# ipro6s register map
Vendor: intelpro; Series: IPRO6S
CPU: ipro6s, little endian
Registers are 32-bit, read-write, reset 0x0 unless marked. A register's access mark holds for its fields unless they carry their own. Offsets are from the block's base; [hi:lo] are bit positions; {n}, {i} and the like mark numbered series.

## MCU_MISC
Base 0x30009000
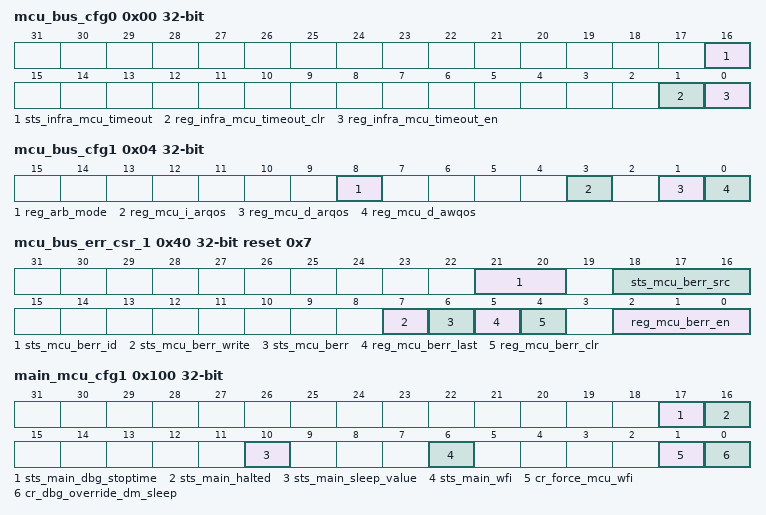
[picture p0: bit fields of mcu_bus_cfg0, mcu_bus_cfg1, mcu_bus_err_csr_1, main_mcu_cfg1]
0x00 mcu_bus_cfg0 (reset mask 0x3)
  [16] sts_infra_mcu_timeout ro — AHB Bus timeout status
  [1] reg_infra_mcu_timeout_clr — Bus timeout clear
  [0] reg_infra_mcu_timeout_en — Bus timeout enable: detect slave no reaponse in 1024 cycles
0x04 mcu_bus_cfg1
  [8] reg_arb_mode — Arbitration mode
  [3] reg_mcu_i_arqos — Main MCU AXI read QoS
  [1] reg_mcu_d_arqos — Main MCU AXI read QoS
  [0] reg_mcu_d_awqos — Main MCU AXI write QoS
0x40 mcu_bus_err_csr_1 reset 0x7 (reset mask 0x37)
  [21:20] sts_mcu_berr_id ro — Error id status
  [18:16] sts_mcu_berr_src ro — bus decode error source index(One hot) [ 0] - rom_tzsrg [ 1] - infra_mmcu_iport [ 2] - infra_mmcu_dport
  [7] sts_mcu_berr_write ro — Bus addr decode error write index
  [6] sts_mcu_berr ro — Bus addr decode error
  [5] reg_mcu_berr_last — Bus addr error monitor latch mode 1'b0 - Latch first error 1'b1 - Latch last error
  [4] reg_mcu_berr_clr — Bus addr decode error clear
  [2:0] reg_mcu_berr_en — bus decode error source index(One hot) [ 0] - rom_tzsrg [ 1] - infra_mmcu_iport [ 2] - infra_mmcu_dport
0x100 main_mcu_cfg1 (reset mask 0x3)
  [17] sts_main_dbg_stoptime ro
  [16] sts_main_halted ro
  [10] sts_main_sleep_value ro — Main MCU low power status
  [6] sts_main_wfi ro — Main MCU wait-for-interrupt status
  [1] cr_force_mcu_wfi
  [0] cr_dbg_override_dm_sleep
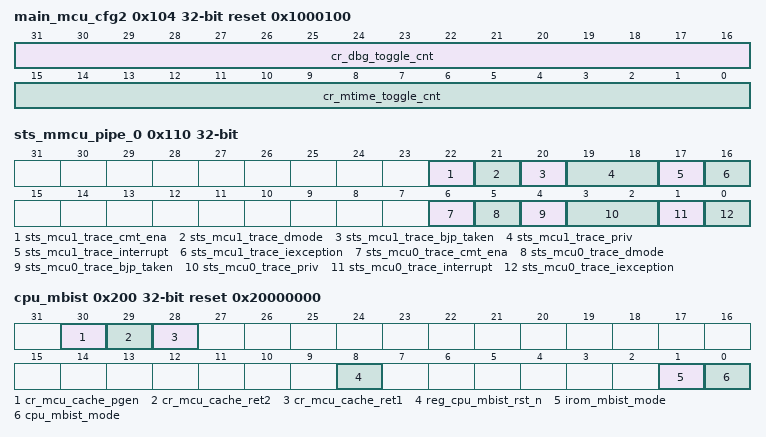
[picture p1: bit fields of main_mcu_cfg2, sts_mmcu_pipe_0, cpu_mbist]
0x104 main_mcu_cfg2 reset 0x1000100
  [31:16] cr_dbg_toggle_cnt, [15:0] cr_mtime_toggle_cnt
0x110 sts_mmcu_pipe_0 reset not defined
  [22] sts_mcu1_trace_cmt_ena ro — Refer to N900 databook
  [21] sts_mcu1_trace_dmode ro
  [20] sts_mcu1_trace_bjp_taken ro
  [19:18] sts_mcu1_trace_priv ro
  [17] sts_mcu1_trace_interrupt ro
  [16] sts_mcu1_trace_iexception ro
  [6] sts_mcu0_trace_cmt_ena ro
  [5] sts_mcu0_trace_dmode ro
  [4] sts_mcu0_trace_bjp_taken ro
  [3:2] sts_mcu0_trace_priv ro
  [1] sts_mcu0_trace_interrupt ro
  [0] sts_mcu0_trace_iexception ro
0x114 sts_mmcu_pipe_1 reset not defined
  [31:0] sts_mcu0_trace_cause ro — Refer to N900 databook
0x118 sts_mmcu_pipe_2 reset not defined
  [31:0] sts_mcu0_trace_tval ro — Refer to N900 databook
0x11C sts_mmcu_pipe_3 reset not defined
  [31:0] sts_mcu0_trace_iaddr ro — Refer to N900 databook
0x120 sts_mmcu_pipe_4 reset not defined
  [31:0] sts_mcu0_trace_instr ro — Refer to N900 databook
0x124 sts_mmcu_pipe_5 reset not defined
  [31:0] sts_mcu1_trace_cause ro — Refer to N900 databook
0x128 sts_mmcu_pipe_6 reset not defined
  [31:0] sts_mcu1_trace_tval ro — Refer to N900 databook
0x12C sts_mmcu_pipe_7 reset not defined
  [31:0] sts_mcu1_trace_iaddr ro — Refer to N900 databook
0x130 sts_mmcu_pipe_8 reset not defined
  [31:0] sts_mcu1_trace_instr ro — Refer to N900 databook
0x200 cpu_mbist reset 0x20000000
  [30] cr_mcu_cache_pgen — CPU Cache Retention
  [29] cr_mcu_cache_ret2 — CPU Cache Sleep
  [28] cr_mcu_cache_ret1 — nap (MCU Cache)
  [8] reg_cpu_mbist_rst_n
  [1] irom_mbist_mode
  [0] cpu_mbist_mode
0x204 cpu_mbist2 reset 0x1560D7FA
  [31] cr_4s_ram_clk_en
  [30:16] cr_ram_bus_mcu_rom
  [14:0] cr_ram_bus_mcu_cache
  [23:0] cr_ram_bus_mcu — [23]=rambus[32]=DVSE [22:19]=rambus[31:28]=DVS [18:17]=ram_bus[27:26]=WABLM_SRAM [16:14]=ram_bus[25:23]=EMA_SRAM [13:12]=ram_bus[22:21]=WABLM_RF [11:10]=ram_bus[20:19]=RAWLM [9]=ram_bus[18]=WABL [8]=ram_bus[17]=RAWL [7:7]=ram_bus[16:15]=EMAW [5:3]=ram_bus[14:12]=EMA_RF [2:0]=ram_bus[11:9]=EMA_ROM

## EF_DATA_1
Base 0x3000C000
{0x40+0x10*i} ef_key_slot_{i}_w0 (i=4..10)
  [31:0] ef_key_slot_{i}_w0 — AES key slot {i}
{0x44+0x10*i} ef_key_slot_{i}_w1 (i=4..10)
  [31:0] ef_key_slot_{i}_w1 — AES key slot {i}
{0x48+0x10*i} ef_key_slot_{i}_w2 (i=4..10)
  [31:0] ef_key_slot_{i}_w2 — AES key slot {i}
{0x4C+0x10*i} ef_key_slot_{i}_w3 (i=4..10)
  [31:0] ef_key_slot_{i}_w3 — AES key slot {i}
{0xF0+4i} ef_dat_1_rsvd_{i} (i=0..2)
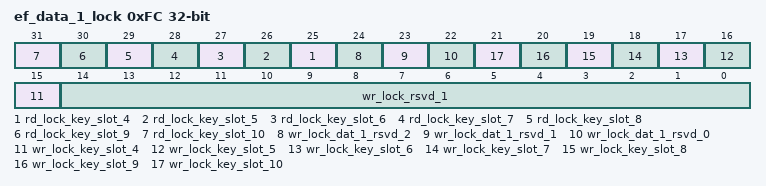
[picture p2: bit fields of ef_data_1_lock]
0xFC ef_data_1_lock
  [n+21] rd_lock_key_slot_{n} (n=4..10), [24] wr_lock_dat_1_rsvd_2, [23] wr_lock_dat_1_rsvd_1, [22] wr_lock_dat_1_rsvd_0, [n+11] wr_lock_key_slot_{n} (n=4..10), [14:0] wr_lock_rsvd_1

## CKS
Base 0x30012000
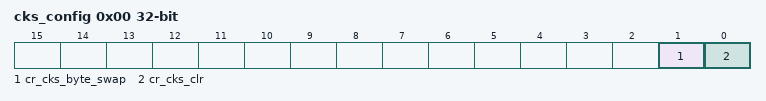
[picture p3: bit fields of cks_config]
0x00 cks_config
  [1] cr_cks_byte_swap — Byte swap signal for each 16-bit data 1'b0: The first data pushed should be the upper byte 1'b1: The first data pushed should be the lower byte
  [0] cr_cks_clr wo — Checksum clear (reset) signal
0x04 data_in
  [7:0] data_in wo — Data input
0x08 cks_out reset not defined
  [15:0] cks_out ro — Checksum output

## MM_MISC
Base 0x30017000
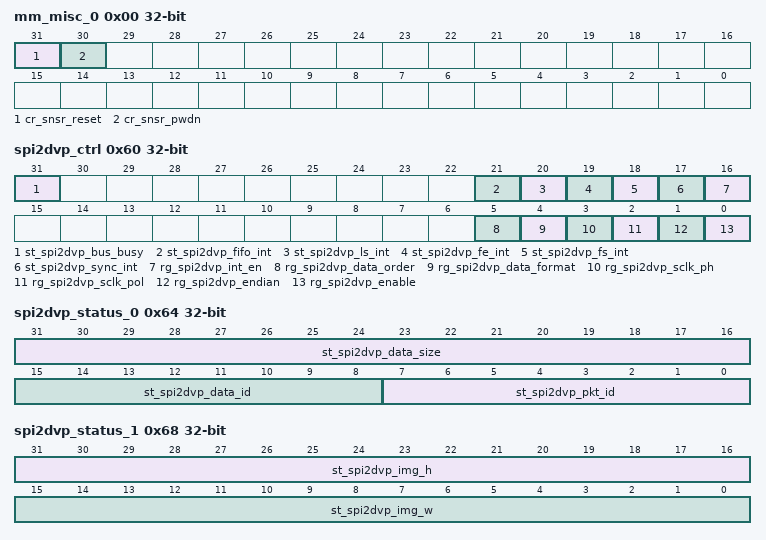
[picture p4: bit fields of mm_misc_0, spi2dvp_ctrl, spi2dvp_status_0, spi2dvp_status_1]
0x00 mm_misc_0
  [31] cr_snsr_reset, [30] cr_snsr_pwdn
0x60 spi2dvp_ctrl (reset mask 0x1003F)
  [31] st_spi2dvp_bus_busy ro — SPI interface busy indicator
  [21] st_spi2dvp_fifo_int ro — FIFO overrun interrupt, considered ERROR and can be cleared by deasserting rg_spi2dvp_int_en
  [20] st_spi2dvp_ls_int ro — Interrupt asserted when Line Start packet is received, can be cleared by deasserting rg_spi2dvp_int_en
  [19] st_spi2dvp_fe_int ro — Interrupt asserted when Frame End packet is received, can be cleared by deasserting rg_spi2dvp_int_en
  [18] st_spi2dvp_fs_int ro — Interrupt asserted when Frame Start packet is received, can be cleared by deasserting rg_spi2dvp_int_en
  [17] st_spi2dvp_sync_int ro — Interrupt asserted when SYNC code is received, can be cleared by deasserting rg_spi2dvp_int_en
  [16] rg_spi2dvp_int_en — SPI2DVP interrupt enable
  [5] rg_spi2dvp_data_order — SPI2DVP data order (don't-care if data format is YUV400) 0: U/V first 1: Y first
  [4] rg_spi2dvp_data_format — SPI2DVP data format 0: YUV422 1: YUV400 (Y only)
  [3] rg_spi2dvp_sclk_ph — SPI interface SCLK phase
  [2] rg_spi2dvp_sclk_pol — SPI interface SCLK polarity
  [1] rg_spi2dvp_endian — SPI interface data endian 0: LSB first 1: MSB first
  [0] rg_spi2dvp_enable — SPI2DVP enable Note : When this bit is set to 1'b1, DVP sensor would be useless
0x64 spi2dvp_status_0 reset not defined
  [31:16] st_spi2dvp_data_size ro — Data size received
  [15:8] st_spi2dvp_data_id ro — Data ID received
  [7:0] st_spi2dvp_pkt_id ro — Packet ID received
0x68 spi2dvp_status_1 reset not defined
  [31:16] st_spi2dvp_img_h ro — Image height received
  [15:0] st_spi2dvp_img_w ro — Image width received
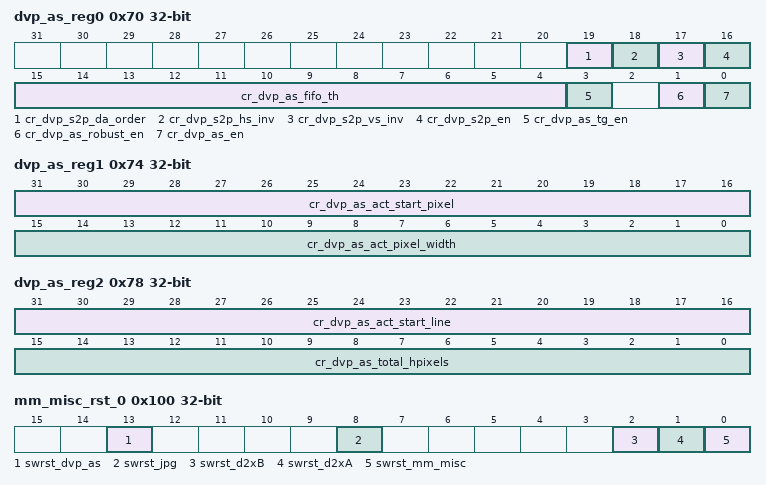
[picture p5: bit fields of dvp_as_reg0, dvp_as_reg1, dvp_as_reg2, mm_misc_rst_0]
0x70 dvp_as_reg0
  [19] cr_dvp_s2p_da_order — Input data order 1'b0: The first data is lower-byte 1'b1: The first data is higher-byte
  [18] cr_dvp_s2p_hs_inv — Input H-Sync inverse signal 1'b0: Input is already active-high (no inverse) 1'b1: Input is active-low (inversed)
  [17] cr_dvp_s2p_vs_inv — Input V-Sync inverse signal 1'b0: Input is already active-high (no inverse) 1'b1: Input is active-low (inversed)
  [16] cr_dvp_s2p_en — Input data format 1'b1: YUV422 1'b0: YUV400 (Y-only)
  [15:4] cr_dvp_as_fifo_th — FIFO threshold for each DVP line to start to output
  [3] cr_dvp_as_tg_en — Auto generate hsync @ H-Blanking
  [1] cr_dvp_as_robust_en — DVP_AS robust enable
  [0] cr_dvp_as_en — Enable signal
0x74 dvp_as_reg1
  [31:16] cr_dvp_as_act_start_pixel — Auto generate hsync @ H-Blanking
  [15:0] cr_dvp_as_act_pixel_width — Auto generate hsync @ H-Blanking
0x78 dvp_as_reg2
  [31:16] cr_dvp_as_act_start_line — Auto generate hsync @ H-Blanking
  [15:0] cr_dvp_as_total_hpixels — Auto generate hsync @ H-Blanking
0x7C dvp_as_reg3
  [15:0] cr_dvp_as_act_line_height — Auto generate hsync @ H-Blanking
0x100 mm_misc_rst_0
  [13] swrst_dvp_as, [8] swrst_jpg, [2] swrst_d2xB, [1] swrst_d2xA, [0] swrst_mm_misc
